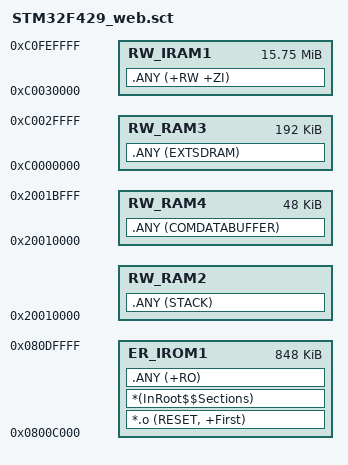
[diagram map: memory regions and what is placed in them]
; *************************************************************
; *** Scatter-Loading Description File generated by uVision ***
; *************************************************************

LR_IROM1 0x0800c000 0x000d4000  {    ; load region size_region
  ER_IROM1 0x0800c000 0x000d4000  {  ; load address = execution address
   *.o (RESET, +First)
   *(InRoot$$Sections)
   .ANY (+RO)
  }
  RW_IRAM1 0xC0030000 0x0FC0000  {  ; RW data
   .ANY (+RW +ZI)
  }
  RW_RAM2  0x20010000 -0x10000     {  ;STACK
   .ANY (STACK)              
  }
  RW_RAM3  0xC0000000 0x30000   { ;RW data ,Rx_recieve buffer
  .ANY (EXTSDRAM)
  }
  RW_RAM4 0x20010000  0xc000  {
  .ANY (COMDATABUFFER)
  } 
}

